VERSION "HIPBNYYYYYYYYYYYYYYYYYYYYYYYYYYYYYYYYYYYYY/4/%%%/4/'%**4YYY///"

NS_ :

BS_:

BU_:

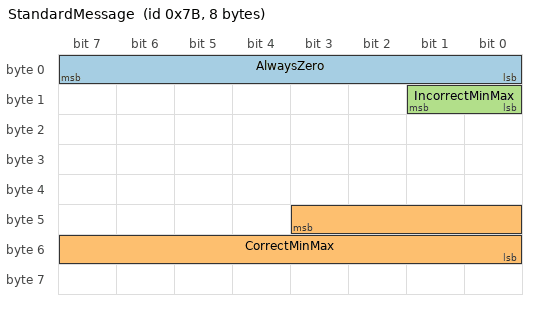
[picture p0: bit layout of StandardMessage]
BO_ 123 StandardMessage: 8 Vector__XXX
 SG_ AlwaysZero : 0|8@1+ (1,0) [0|0] "A" Vector__XXX
 SG_ CorrectMinMax : 43|12@0- (0.5,-50) [-5|5] "V" Vector__XXX
 SG_ IncorrectMinMax : 8|2@1+ (1,0) [5|-5] "" Vector__XXX
